# ML630Q464 register map
Vendor: LAPIS Semiconductor Co.,Ltd.; File version: 1.00
CPU: CM0PLUS r0p1, little endian, no MPU, no FPU, 2 interrupt priority bits
Registers are 32-bit, read-write, no defined reset value unless marked. A register's access mark holds for its fields unless they carry their own. Offsets are from the block's base; [hi:lo] are bit positions; {n}, {i} and the like mark numbered series.

## FTIMER
Base 0x5C003000
{0x0+0x100*i} FT{i}P (i=0..3) — FTM{i} period register
  [15:0] FTnP
{0x4+0x100*i} FT{i}EA (i=0..3) — FTM{i} event register A
  [15:0] FTnEA
{0x8+0x100*i} FT{i}EB (i=0..3) — FTM{i} event register B
  [15:0] FTnEB
{0xC+0x100*i} FT{i}DT (i=0..3) — FTM{i} dead time register
  [15:0] FTnDT
{0x10+0x100*i} FT{i}C (i=0..3) — FTM{i} counter register
  [15:0] FTnC
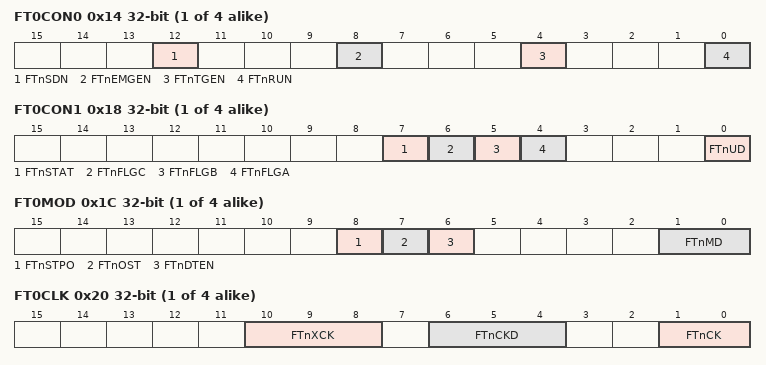
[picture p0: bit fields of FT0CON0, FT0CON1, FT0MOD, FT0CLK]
{0x14+0x100*i} FT{i}CON0 (i=0..3) — FTM{i} control register 0
  [12] FTnSDN, [8] FTnEMGEN, [4] FTnTGEN, [0] FTnRUN
{0x18+0x100*i} FT{i}CON1 access per field (i=0..3) — FTM{i} control register 1
  [7] FTnSTAT ro, [6] FTnFLGC ro, [5] FTnFLGB ro, [4] FTnFLGA ro, [0] FTnUD rw
{0x1C+0x100*i} FT{i}MOD (i=0..3) — FTM{i} mode register
  [8] FTnSTPO, [7] FTnOST, [6] FTnDTEN, [1:0] FTnMD
{0x20+0x100*i} FT{i}CLK (i=0..3) — FTM{i} clock register
  [10:8] FTnXCK, [6:4] FTnCKD, [1:0] FTnCK
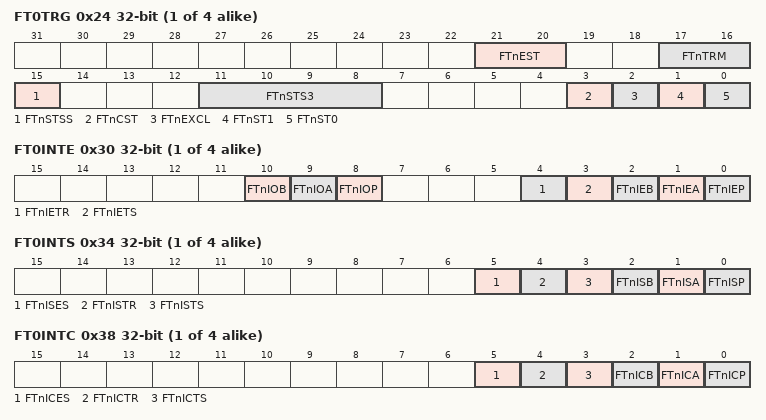
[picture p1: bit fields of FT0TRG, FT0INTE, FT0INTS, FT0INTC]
{0x24+0x100*i} FT{i}TRG (i=0..3) — FTM{i} trigger register
  [21:20] FTnEST, [17:16] FTnTRM, [15] FTnSTSS, [11:8] FTnSTS3, [3] FTnCST, [2] FTnEXCL, [1] FTnST1, [0] FTnST0
{0x30+0x100*i} FT{i}INTE (i=0..3) — FTM{i} interrupt enable register
  [10] FTnIOB, [9] FTnIOA, [8] FTnIOP, [4] FTnIETR, [3] FTnIETS, [2] FTnIEB, [1] FTnIEA, [0] FTnIEP
{0x34+0x100*i} FT{i}INTS ro (i=0..3) — FTM{i} interrupt status register
  [5] FTnISES, [4] FTnISTR, [3] FTnISTS, [2] FTnISB, [1] FTnISA, [0] FTnISP
{0x38+0x100*i} FT{i}INTC wo (i=0..3) — FTM{i} interrupt clear register
  [5] FTnICES, [4] FTnICTR, [3] FTnICTS, [2] FTnICB, [1] FTnICA, [0] FTnICP
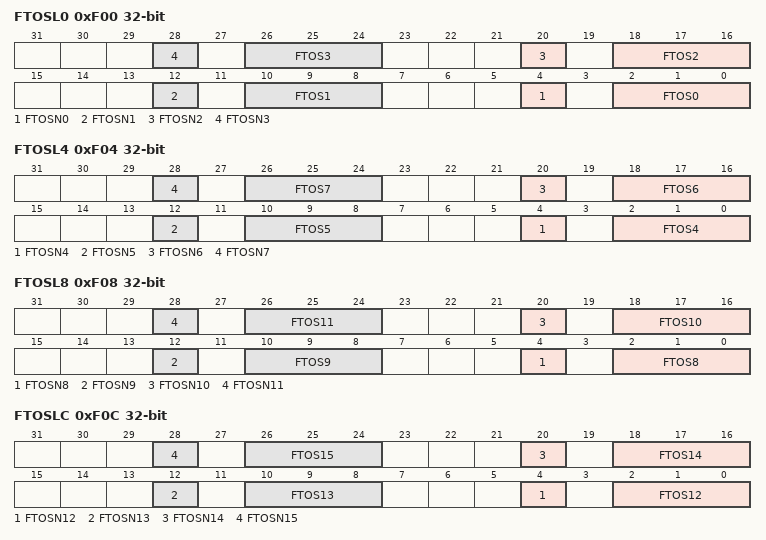
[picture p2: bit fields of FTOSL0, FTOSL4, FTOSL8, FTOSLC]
0xF00 FTOSL0 wo — FTM output select register 0
  [8n+4] FTOSN{n} (n=0..3), [8n+2:8n] FTOS{n} (n=0..3)
0xF04 FTOSL4 wo — FTM output select register 4
  [8n-28] FTOSN{n} (n=4..7), [8n-30:8n-32] FTOS{n} (n=4..7)
0xF08 FTOSL8 wo — FTM output select register 8
  [8n-60] FTOSN{n} (n=8..11), [8n-62:8n-64] FTOS{n} (n=8..11)
0xF0C FTOSLC wo — FTM output select register C
  [8n-92] FTOSN{n} (n=12..15), [8n-94:8n-96] FTOS{n} (n=12..15)

## RTC
Base 0x5C002300
0x00 RTCSEC — Real time clock second register
  [6:0] RS
0x04 RTCMIN — Real time clock minute register
  [6:0] RM
0x08 RTCHOUR — Real time clock hour register
  [5:0] RH
0x0C RTCWEEK — Real time clock week register
  [2:0] RW
0x10 RTCDAY — Real time clock day register
  [5:0] RD
0x14 RTCMON — Real time clock month register
  [4:0] RMO
0x18 RTCYEAR — Real time clock year register
  [7:0] RY
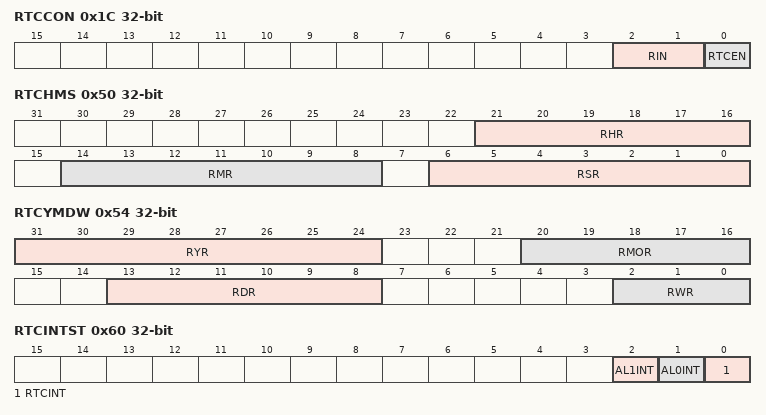
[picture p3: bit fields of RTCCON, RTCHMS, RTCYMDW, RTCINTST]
0x1C RTCCON — Real time clock control register
  [2:1] RIN, [0] RTCEN
0x20 AL0MIN — Real time clock alarm 0 minute register
  [6:0] AL0M
0x24 AL0HOUR — Real time clock alarm 0 hour register
  [5:0] AL0H
0x28 AL0WEEK — Real time clock alarm 0 week register
  [2:0] AL0W
0x2C AL1MIN — Real time clock alarm 1 minute register
  [6:0] AL1M
0x30 AL1HOUR — Real time clock alarm 1 hour register
  [5:0] AL1H
0x34 AL1DAY — Real time clock alarm 1 day register
  [5:0] AL1D
0x38 AL1MON — Real time clock alarm 1 month register
  [4:0] AL1MO
0x50 RTCHMS ro — Real time clock hour/minute/second register
  [21:16] RHR, [14:8] RMR, [6:0] RSR
0x54 RTCYMDW ro — Real time clock year/month/day/week register
  [31:24] RYR, [20:16] RMOR, [13:8] RDR, [2:0] RWR
0x60 RTCINTST — Real time clock interrupt statusregister
  [2] AL1INT, [1] AL0INT, [0] RTCINT

## TIMER1K
Base 0x5C002200
0x00 T1KCRL — 1 kHz timer count register
  [12:0] T1KC
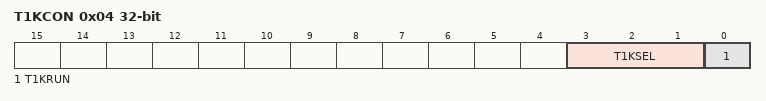
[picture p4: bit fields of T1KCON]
0x04 T1KCON — 1 kHz timer control register
  [3:1] T1KSEL, [0] T1KRUN

## WDT
Base 0x5C002000
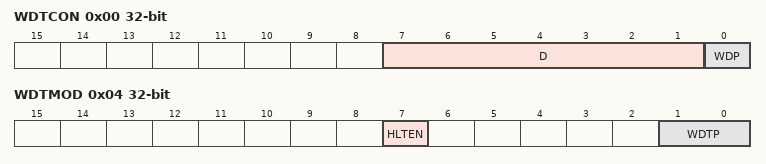
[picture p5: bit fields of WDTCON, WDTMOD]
0x00 WDTCON access per field — Watchdog timer control register
  [7:1] D wo, [0] WDP rw
0x04 WDTMOD — Watchdog timer mode register
  [7] HLTEN, [1:0] WDTP

## SSIOF0
Base 0x41000800
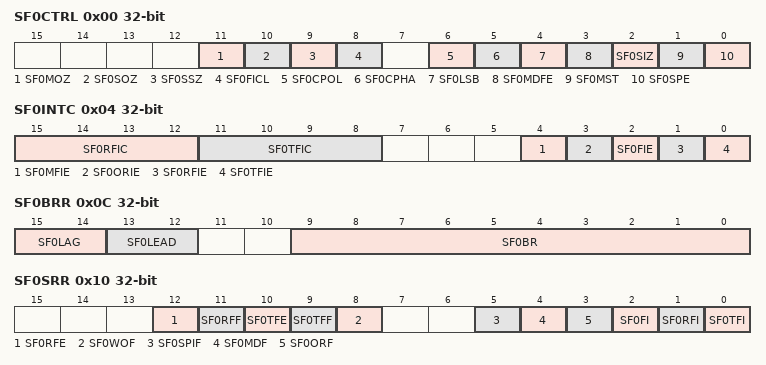
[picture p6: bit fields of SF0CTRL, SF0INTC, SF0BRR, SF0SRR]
0x00 SF0CTRL — SIOF0 control register
  [11] SF0MOZ, [10] SF0SOZ, [9] SF0SSZ, [8] SF0FICL, [6] SF0CPOL, [5] SF0CPHA, [4] SF0LSB, [3] SF0MDFE, [2] SF0SIZ, [1] SF0MST, [0] SF0SPE
0x04 SF0INTC — SIOF0 interrupt control register
  [15:12] SF0RFIC, [11:8] SF0TFIC, [4] SF0MFIE, [3] SF0ORIE, [2] SF0FIE, [1] SF0RFIE, [0] SF0TFIE
0x08 SF0TRAC — SIOF0 transfer interval control register
  [8:0] SF0DTL
0x0C SF0BRR — SIOF0 baud rate register
  [15:14] SF0LAG, [13:12] SF0LEAD, [9:0] SF0BR
0x10 SF0SRR ro — SIOF0 status register
  [12] SF0RFE, [11] SF0RFF, [10] SF0TFE, [9] SF0TFF, [8] SF0WOF, [5] SF0SPIF, [4] SF0MDF, [3] SF0ORF, [2] SF0FI, [1] SF0RFI, [0] SF0TFI
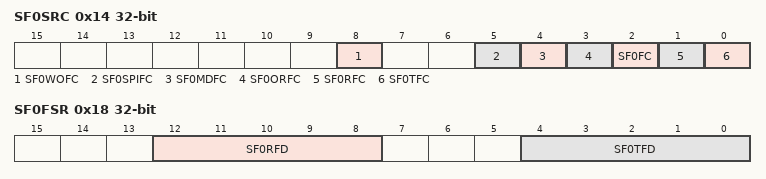
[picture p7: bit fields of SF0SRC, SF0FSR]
0x14 SF0SRC wo — SIOF0 status clear register
  [8] SF0WOFC, [5] SF0SPIFC, [4] SF0MDFC, [3] SF0ORFC, [2] SF0FC, [1] SF0RFC, [0] SF0TFC
0x18 SF0FSR ro — SIOF0 FIFO status register
  [12:8] SF0RFD, [4:0] SF0TFD
0x1C SF0DWR — SIOF0 write data register
  [15:0] SF0WD
0x20 SF0DRR ro — SIOF0 read data register
  [15:0] SF0RD
